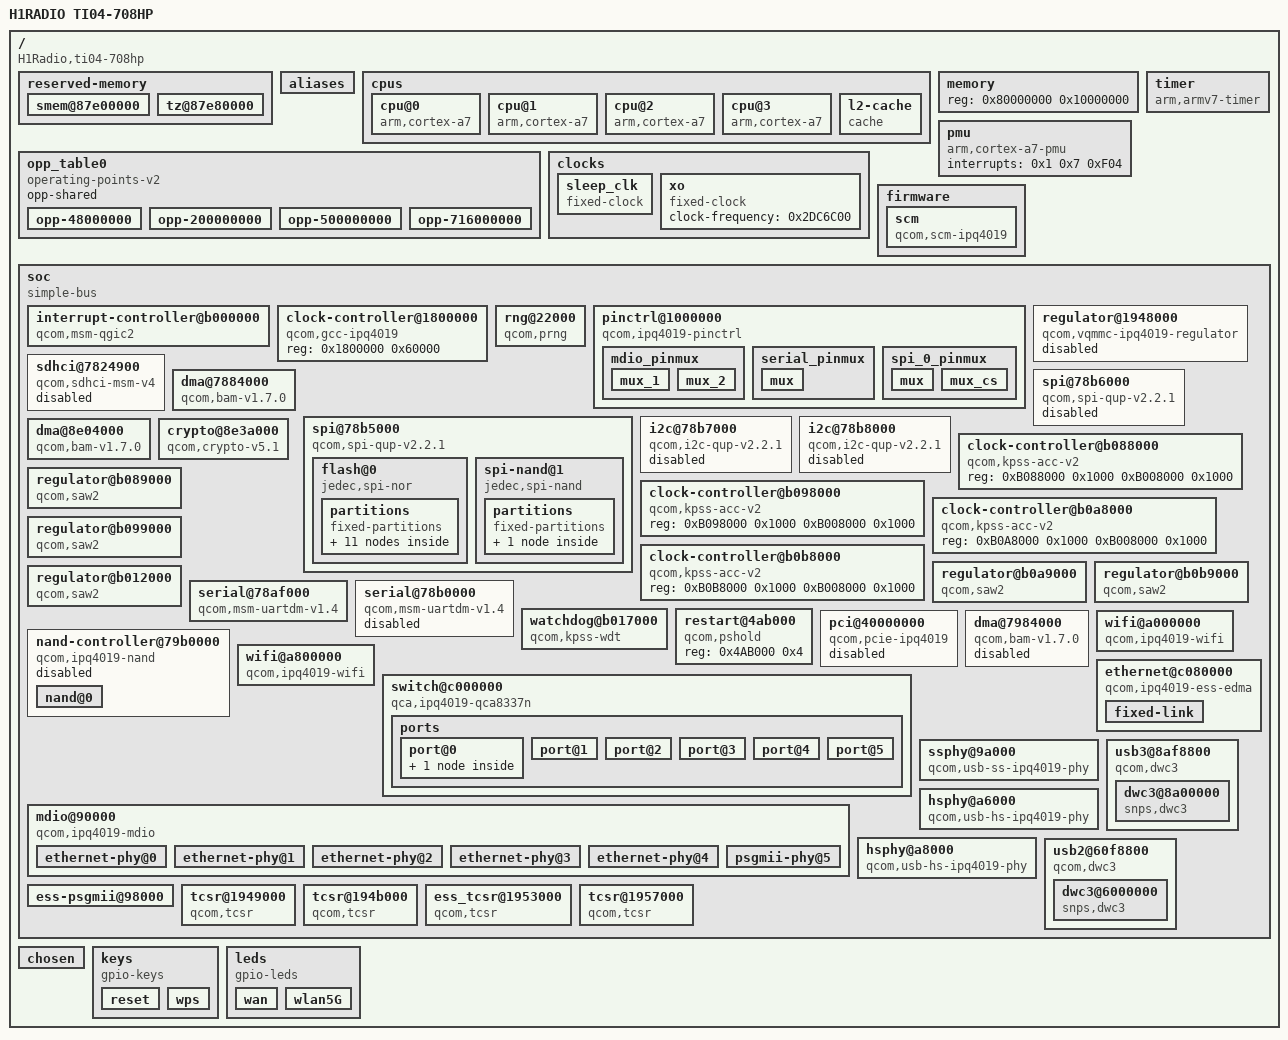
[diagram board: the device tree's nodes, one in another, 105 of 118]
/dts-v1/;
// version: 17
// last_comp_version: 16
// boot_cpuid_phys: 0x0

/ {
    #address-cells = <0x1>;
    #size-cells = <0x1>;
    model = "H1RADIO TI04-708HP";
    compatible = "H1Radio,ti04-708hp";
    interrupt-parent = <0x1>;
    reserved-memory {
        #address-cells = <0x1>;
        #size-cells = <0x1>;
        ranges;
        smem@87e00000 {
            reg = <0x87E00000 0x80000>;
            no-map;
        };
        tz@87e80000 {
            reg = <0x87E80000 0x180000>;
            no-map;
        };
    };
    aliases {
        spi0 = "/soc/spi@78b5000";
        spi1 = "/soc/spi@78b6000";
        i2c0 = "/soc/i2c@78b7000";
        i2c1 = "/soc/i2c@78b8000";
        ethernet0 = "/soc/ethernet@c080000";
        led-boot = "/leds/wan";
        led-failsafe = "/leds/wan";
        led-upgrade = "/leds/wan";
    };
    cpus {
        #address-cells = <0x1>;
        #size-cells = <0x0>;
        cpu@0 {
            device_type = "cpu";
            compatible = "arm,cortex-a7";
            enable-method = "qcom,kpss-acc-v2";
            next-level-cache = <0x2>;
            qcom,acc = <0x3>;
            qcom,saw = <0x4>;
            reg = <0x0>;
            clocks = <0x5 0x9>;
            clock-frequency = <0x0>;
            clock-latency = <0x3E800>;
            operating-points-v2 = <0x6>;
        };
        cpu@1 {
            device_type = "cpu";
            compatible = "arm,cortex-a7";
            enable-method = "qcom,kpss-acc-v2";
            next-level-cache = <0x2>;
            qcom,acc = <0x7>;
            qcom,saw = <0x8>;
            reg = <0x1>;
            clocks = <0x5 0x9>;
            clock-frequency = <0x0>;
            clock-latency = <0x3E800>;
            operating-points-v2 = <0x6>;
        };
        cpu@2 {
            device_type = "cpu";
            compatible = "arm,cortex-a7";
            enable-method = "qcom,kpss-acc-v2";
            next-level-cache = <0x2>;
            qcom,acc = <0x9>;
            qcom,saw = <0xA>;
            reg = <0x2>;
            clocks = <0x5 0x9>;
            clock-frequency = <0x0>;
            clock-latency = <0x3E800>;
            operating-points-v2 = <0x6>;
        };
        cpu@3 {
            device_type = "cpu";
            compatible = "arm,cortex-a7";
            enable-method = "qcom,kpss-acc-v2";
            next-level-cache = <0x2>;
            qcom,acc = <0xB>;
            qcom,saw = <0xC>;
            reg = <0x3>;
            clocks = <0x5 0x9>;
            clock-frequency = <0x0>;
            clock-latency = <0x3E800>;
            operating-points-v2 = <0x6>;
        };
        l2-cache {
            compatible = "cache";
            cache-level = <0x2>;
            qcom,saw = <0xD>;
            phandle = <0x2>;
        };
    };
    opp_table0 {
        compatible = "operating-points-v2";
        opp-shared;
        phandle = <0x6>;
        opp-48000000 {
            opp-hz = <0x0 0x2DC6C00>;
            clock-latency-ns = <0x3E800>;
        };
        opp-200000000 {
            opp-hz = <0x0 0xBEBC200>;
            clock-latency-ns = <0x3E800>;
        };
        opp-500000000 {
            opp-hz = <0x0 0x1DCD6500>;
            clock-latency-ns = <0x3E800>;
        };
        opp-716000000 {
            opp-hz = <0x0 0x2AAD4B00>;
            clock-latency-ns = <0x3E800>;
        };
    };
    memory {
        device_type = "memory";
        reg = <0x80000000 0x10000000>;
    };
    pmu {
        compatible = "arm,cortex-a7-pmu";
        interrupts = <0x1 0x7 0xF04>;
    };
    clocks {
        sleep_clk {
            compatible = "fixed-clock";
            clock-frequency = <0x7D00>;
            clock-output-names = "gcc_sleep_clk_src";
            #clock-cells = <0x0>;
            phandle = <0x13>;
        };
        xo {
            compatible = "fixed-clock";
            clock-frequency = <0x2DC6C00>;
            #clock-cells = <0x0>;
        };
    };
    firmware {
        scm {
            compatible = "qcom,scm-ipq4019";
        };
    };
    timer {
        compatible = "arm,armv7-timer";
        interrupts = <0x1 0x2 0xF08 0x1 0x3 0xF08 0x1 0x4 0xF08 0x1 0x1 0xF08>;
        clock-frequency = <0x2DC6C00>;
        always-on;
    };
    soc {
        #address-cells = <0x1>;
        #size-cells = <0x1>;
        ranges;
        compatible = "simple-bus";
        interrupt-controller@b000000 {
            compatible = "qcom,msm-qgic2";
            interrupt-controller;
            #interrupt-cells = <0x3>;
            reg = <0xB000000 0x1000 0xB002000 0x1000>;
            phandle = <0x1>;
        };
        clock-controller@1800000 {
            compatible = "qcom,gcc-ipq4019";
            #clock-cells = <0x1>;
            #reset-cells = <0x1>;
            reg = <0x1800000 0x60000>;
            phandle = <0x5>;
        };
        rng@22000 {
            compatible = "qcom,prng";
            reg = <0x22000 0x140>;
            clocks = <0x5 0x2B>;
            clock-names = "core";
            status = "okay";
        };
        pinctrl@1000000 {
            compatible = "qcom,ipq4019-pinctrl";
            reg = <0x1000000 0x300000>;
            gpio-controller;
            gpio-ranges = <0xE 0x0 0x0 0x64>;
            #gpio-cells = <0x2>;
            interrupt-controller;
            #interrupt-cells = <0x2>;
            interrupts = <0x0 0xD0 0x4>;
            phandle = <0xE>;
            mdio_pinmux {
                phandle = <0x20>;
                mux_1 {
                    pins = "gpio53";
                    function = "mdio";
                    bias-pull-up;
                };
                mux_2 {
                    pins = "gpio52";
                    function = "mdc";
                    bias-pull-up;
                };
            };
            serial_pinmux {
                phandle = <0x12>;
                mux {
                    pins = "gpio60", "gpio61";
                    function = "blsp_uart0";
                    bias-disable;
                };
            };
            spi_0_pinmux {
                phandle = <0x10>;
                mux {
                    function = "blsp_spi0";
                    pins = "gpio55", "gpio56", "gpio57";
                    drive-strength = <0xC>;
                    bias-disable;
                };
                mux_cs {
                    function = "gpio";
                    pins = "gpio54", "gpio59";
                    drive-strength = <0x2>;
                    bias-disable;
                    output-high;
                };
            };
        };
        regulator@1948000 {
            compatible = "qcom,vqmmc-ipq4019-regulator";
            reg = <0x1948000 0x4>;
            regulator-name = "vqmmc";
            regulator-min-microvolt = <0x16E360>;
            regulator-max-microvolt = <0x2DC6C0>;
            regulator-always-on;
            status = "disabled";
        };
        sdhci@7824900 {
            compatible = "qcom,sdhci-msm-v4";
            reg = <0x7824900 0x11C 0x7824000 0x800>;
            interrupts = <0x0 0x7B 0x4 0x0 0x8A 0x4>;
            interrupt-names = "hc_irq", "pwr_irq";
            bus-width = <0x8>;
            clocks = <0x5 0x2F 0x5 0x2E 0x5 0x1C>;
            clock-names = "core", "iface", "xo";
            status = "disabled";
        };
        dma@7884000 {
            compatible = "qcom,bam-v1.7.0";
            reg = <0x7884000 0x23000>;
            interrupts = <0x0 0xEE 0x4>;
            clocks = <0x5 0x15>;
            clock-names = "bam_clk";
            #dma-cells = <0x1>;
            qcom,ee = <0x0>;
            status = "okay";
            phandle = <0xF>;
        };
        spi@78b5000 {
            compatible = "qcom,spi-qup-v2.2.1";
            reg = <0x78B5000 0x600>;
            interrupts = <0x0 0x5F 0x4>;
            clocks = <0x5 0x17 0x5 0x15>;
            clock-names = "core", "iface";
            #address-cells = <0x1>;
            #size-cells = <0x0>;
            dmas = <0xF 0x5 0xF 0x4>;
            dma-names = "rx", "tx";
            status = "okay";
            pinctrl-0 = <0x10>;
            pinctrl-names = "default";
            cs-gpios = <0xE 0x36 0x0 0xE 0x3B 0x0>;
            flash@0 {
                compatible = "jedec,spi-nor";
                reg = <0x0>;
                linux,modalias = "m25p80", "mx25l1606e", "n25q128a11";
                spi-max-frequency = <0x1C9C380>;
                partitions {
                    compatible = "fixed-partitions";
                    #address-cells = <0x1>;
                    #size-cells = <0x1>;
                    partition@0 {
                        label = "SBL1";
                        reg = <0x0 0x40000>;
                        read-only;
                    };
                    partition@40000 {
                        label = "MIBIB";
                        reg = <0x40000 0x20000>;
                        read-only;
                    };
                    partition@60000 {
                        label = "QSEE";
                        reg = <0x60000 0x60000>;
                        read-only;
                    };
                    partition@c0000 {
                        label = "CDT";
                        reg = <0xC0000 0x10000>;
                        read-only;
                    };
                    partition@d0000 {
                        label = "DDRPARAMS";
                        reg = <0xD0000 0x10000>;
                        read-only;
                    };
                    partition@e0000 {
                        label = "APPSBLENV";
                        reg = <0xE0000 0x10000>;
                        read-only;
                    };
                    partition@f0000 {
                        label = "APPSBL";
                        reg = <0xF0000 0x80000>;
                        read-only;
                    };
                    partition@170000 {
                        label = "ART";
                        reg = <0x170000 0x10000>;
                        read-only;
                        compatible = "nvmem-cells";
                        macaddr@0006 {
                            reg = <0x6 0x6>;
                            phandle = <0x16>;
                        };
                        precal@1000 {
                            reg = <0x1000 0x2F20>;
                            phandle = <0x15>;
                        };
                        precal@5000 {
                            reg = <0x5000 0x2F20>;
                            phandle = <0x17>;
                        };
                    };
                };
            };
            spi-nand@1 {
                compatible = "jedec,spi-nand", "spinand,mt29f";
                #address-cells = <0x1>;
                #size-cells = <0x1>;
                reg = <0x1>;
                spi-max-frequency = <0x16E3600>;
                partitions {
                    compatible = "fixed-partitions";
                    #address-cells = <0x1>;
                    #size-cells = <0x1>;
                    partition@0 {
                        label = "ubi";
                        reg = <0x0 0x8000000>;
                    };
                };
            };
        };
        spi@78b6000 {
            compatible = "qcom,spi-qup-v2.2.1";
            reg = <0x78B6000 0x600>;
            interrupts = <0x0 0x60 0x4>;
            clocks = <0x5 0x19 0x5 0x15>;
            clock-names = "core", "iface";
            #address-cells = <0x1>;
            #size-cells = <0x0>;
            dmas = <0xF 0x7 0xF 0x6>;
            dma-names = "rx", "tx";
            status = "disabled";
        };
        i2c@78b7000 {
            compatible = "qcom,i2c-qup-v2.2.1";
            reg = <0x78B7000 0x600>;
            interrupts = <0x0 0x61 0x4>;
            clocks = <0x5 0x15 0x5 0x16>;
            clock-names = "iface", "core";
            #address-cells = <0x1>;
            #size-cells = <0x0>;
            dmas = <0xF 0x9 0xF 0x8>;
            dma-names = "rx", "tx";
            status = "disabled";
        };
        i2c@78b8000 {
            compatible = "qcom,i2c-qup-v2.2.1";
            reg = <0x78B8000 0x600>;
            interrupts = <0x0 0x62 0x4>;
            clocks = <0x5 0x15 0x5 0x18>;
            clock-names = "iface", "core";
            #address-cells = <0x1>;
            #size-cells = <0x0>;
            dmas = <0xF 0xB 0xF 0xA>;
            dma-names = "rx", "tx";
            status = "disabled";
        };
        dma@8e04000 {
            compatible = "qcom,bam-v1.7.0";
            reg = <0x8E04000 0x20000>;
            interrupts = <0x0 0xCF 0x4>;
            clocks = <0x5 0x21>;
            clock-names = "bam_clk";
            #dma-cells = <0x1>;
            qcom,ee = <0x1>;
            qcom,controlled-remotely;
            status = "okay";
            phandle = <0x11>;
        };
        crypto@8e3a000 {
            compatible = "qcom,crypto-v5.1";
            reg = <0x8E3A000 0x6000>;
            clocks = <0x5 0x21 0x5 0x22 0x5 0x23>;
            clock-names = "iface", "bus", "core";
            dmas = <0x11 0x2 0x11 0x3>;
            dma-names = "rx", "tx";
            status = "okay";
        };
        clock-controller@b088000 {
            compatible = "qcom,kpss-acc-v2";
            reg = <0xB088000 0x1000 0xB008000 0x1000>;
            phandle = <0x3>;
        };
        clock-controller@b098000 {
            compatible = "qcom,kpss-acc-v2";
            reg = <0xB098000 0x1000 0xB008000 0x1000>;
            phandle = <0x7>;
        };
        clock-controller@b0a8000 {
            compatible = "qcom,kpss-acc-v2";
            reg = <0xB0A8000 0x1000 0xB008000 0x1000>;
            phandle = <0x9>;
        };
        clock-controller@b0b8000 {
            compatible = "qcom,kpss-acc-v2";
            reg = <0xB0B8000 0x1000 0xB008000 0x1000>;
            phandle = <0xB>;
        };
        regulator@b089000 {
            compatible = "qcom,saw2";
            reg = <0xB089000 0x1000 0xB009000 0x1000>;
            regulator;
            phandle = <0x4>;
        };
        regulator@b099000 {
            compatible = "qcom,saw2";
            reg = <0xB099000 0x1000 0xB009000 0x1000>;
            regulator;
            phandle = <0x8>;
        };
        regulator@b0a9000 {
            compatible = "qcom,saw2";
            reg = <0xB0A9000 0x1000 0xB009000 0x1000>;
            regulator;
            phandle = <0xA>;
        };
        regulator@b0b9000 {
            compatible = "qcom,saw2";
            reg = <0xB0B9000 0x1000 0xB009000 0x1000>;
            regulator;
            phandle = <0xC>;
        };
        regulator@b012000 {
            compatible = "qcom,saw2";
            reg = <0xB012000 0x1000>;
            regulator;
            phandle = <0xD>;
        };
        serial@78af000 {
            compatible = "qcom,msm-uartdm-v1.4", "qcom,msm-uartdm";
            reg = <0x78AF000 0x200>;
            interrupts = <0x0 0x6B 0x4>;
            status = "okay";
            clocks = <0x5 0x1A 0x5 0x15>;
            clock-names = "core", "iface";
            dmas = <0xF 0x1 0xF 0x0>;
            dma-names = "rx", "tx";
            pinctrl-0 = <0x12>;
            pinctrl-names = "default";
        };
        serial@78b0000 {
            compatible = "qcom,msm-uartdm-v1.4", "qcom,msm-uartdm";
            reg = <0x78B0000 0x200>;
            interrupts = <0x0 0x6C 0x4>;
            status = "disabled";
            clocks = <0x5 0x1B 0x5 0x15>;
            clock-names = "core", "iface";
            dmas = <0xF 0x3 0xF 0x2>;
            dma-names = "rx", "tx";
        };
        watchdog@b017000 {
            compatible = "qcom,kpss-wdt", "qcom,kpss-wdt-ipq4019";
            reg = <0xB017000 0x40>;
            clocks = <0x13>;
            timeout-sec = <0xA>;
            status = "okay";
        };
        restart@4ab000 {
            compatible = "qcom,pshold";
            reg = <0x4AB000 0x4>;
        };
        pci@40000000 {
            compatible = "qcom,pcie-ipq4019", "snps,dw-pcie";
            reg = <0x40000000 0xF1D 0x40000F20 0xA8 0x80000 0x2000 0x40100000 0x1000>;
            reg-names = "dbi", "elbi", "parf", "config";
            device_type = "pci";
            linux,pci-domain = <0x0>;
            bus-range = <0x0 0xFF>;
            num-lanes = <0x1>;
            #address-cells = <0x3>;
            #size-cells = <0x2>;
            ranges = <0x81000000 0x0 0x0 0x40200000 0x0 0x100000 0x82000000 0x0 0x40300000 0x40300000 0x0 0xD00000>;
            interrupts = <0x0 0x8D 0x4>;
            interrupt-names = "msi";
            #interrupt-cells = <0x1>;
            interrupt-map-mask = <0x0 0x0 0x0 0x7>;
            interrupt-map = <0x0 0x0 0x0 0x1 0x1 0x0 0x8E 0x4 0x0 0x0 0x0 0x2 0x1 0x0 0x8F 0x4 0x0 0x0 0x0 0x3 0x1 0x0 0x90 0x4 0x0 0x0 0x0 0x4 0x1 0x0 0x91 0x4>;
            clocks = <0x5 0x27 0x5 0x28 0x5 0x29>;
            clock-names = "aux", "master_bus", "slave_bus";
            resets = <0x5 0x1C 0x5 0x1B 0x5 0x1A 0x5 0x19 0x5 0x18 0x5 0x17 0x5 0x16 0x5 0x15 0x5 0x14 0x5 0x13 0x5 0x12 0x5 0x11>;
            reset-names = "axi_m", "axi_s", "pipe", "axi_m_vmid", "axi_s_xpu", "parf", "phy", "axi_m_sticky", "pipe_sticky", "pwr", "ahb", "phy_ahb";
            status = "disabled";
        };
        dma@7984000 {
            compatible = "qcom,bam-v1.7.0";
            reg = <0x7984000 0x1A000>;
            interrupts = <0x0 0x65 0x4>;
            clocks = <0x5 0x2D>;
            clock-names = "bam_clk";
            #dma-cells = <0x1>;
            qcom,ee = <0x0>;
            status = "disabled";
            phandle = <0x14>;
        };
        nand-controller@79b0000 {
            compatible = "qcom,ipq4019-nand";
            reg = <0x79B0000 0x1000>;
            #address-cells = <0x1>;
            #size-cells = <0x0>;
            clocks = <0x5 0x2D 0x5 0x2C>;
            clock-names = "core", "aon";
            dmas = <0x14 0x0 0x14 0x1 0x14 0x2>;
            dma-names = "tx", "rx", "cmd";
            status = "disabled";
            nand@0 {
                reg = <0x0>;
                nand-ecc-strength = <0x4>;
                nand-ecc-step-size = <0x200>;
                nand-bus-width = <0x8>;
            };
        };
        wifi@a000000 {
            compatible = "qcom,ipq4019-wifi";
            reg = <0xA000000 0x200000>;
            resets = <0x5 0x0 0x5 0x1 0x5 0x2 0x5 0x3 0x5 0x4 0x5 0x5>;
            reset-names = "wifi_cpu_init", "wifi_radio_srif", "wifi_radio_warm", "wifi_radio_cold", "wifi_core_warm", "wifi_core_cold";
            clocks = <0x5 0x3B 0x5 0x3C 0x5 0x3D>;
            clock-names = "wifi_wcss_cmd", "wifi_wcss_ref", "wifi_wcss_rtc";
            interrupts = <0x0 0x20 0x1 0x0 0x21 0x1 0x0 0x22 0x1 0x0 0x23 0x1 0x0 0x24 0x1 0x0 0x25 0x1 0x0 0x26 0x1 0x0 0x27 0x1 0x0 0x28 0x1 0x0 0x29 0x1 0x0 0x2A 0x1 0x0 0x2B 0x1 0x0 0x2C 0x1 0x0 0x2D 0x1 0x0 0x2E 0x1 0x0 0x2F 0x1 0x0 0xA8 0x4>;
            interrupt-names = "msi0", "msi1", "msi2", "msi3", "msi4", "msi5", "msi6", "msi7", "msi8", "msi9", "msi10", "msi11", "msi12", "msi13", "msi14", "msi15", "legacy";
            status = "okay";
            nvmem-cell-names = "pre-calibration", "mac-address";
            nvmem-cells = <0x15 0x16>;
            qcom,ath10k-calibration-variant = "8devices-Jalapeno";
        };
        wifi@a800000 {
            compatible = "qcom,ipq4019-wifi";
            reg = <0xA800000 0x200000>;
            resets = <0x5 0x6 0x5 0x7 0x5 0x8 0x5 0x9 0x5 0xA 0x5 0xB>;
            reset-names = "wifi_cpu_init", "wifi_radio_srif", "wifi_radio_warm", "wifi_radio_cold", "wifi_core_warm", "wifi_core_cold";
            clocks = <0x5 0x3E 0x5 0x3F 0x5 0x40>;
            clock-names = "wifi_wcss_cmd", "wifi_wcss_ref", "wifi_wcss_rtc";
            interrupts = <0x0 0x30 0x1 0x0 0x31 0x1 0x0 0x32 0x1 0x0 0x33 0x1 0x0 0x34 0x1 0x0 0x35 0x1 0x0 0x36 0x1 0x0 0x37 0x1 0x0 0x38 0x1 0x0 0x39 0x1 0x0 0x3A 0x1 0x0 0x3B 0x1 0x0 0x3C 0x1 0x0 0x3D 0x1 0x0 0x3E 0x1 0x0 0x3F 0x1 0x0 0xA9 0x4>;
            interrupt-names = "msi0", "msi1", "msi2", "msi3", "msi4", "msi5", "msi6", "msi7", "msi8", "msi9", "msi10", "msi11", "msi12", "msi13", "msi14", "msi15", "legacy";
            status = "okay";
            nvmem-cell-names = "pre-calibration", "mac-address";
            nvmem-cells = <0x17 0x16>;
            mac-address-increment = <0x1>;
            qcom,ath10k-calibration-variant = "8devices-Jalapeno";
        };
        switch@c000000 {
            compatible = "qca,ipq4019-qca8337n";
            reg = <0xC000000 0x80000 0x98000 0x800>;
            reg-names = "base", "psgmii_phy";
            resets = <0x5 0x4D>;
            reset-names = "psgmii_rst";
            mdio = <0x18>;
            psgmii-ethphy = <0x19>;
            status = "okay";
            ports {
                #address-cells = <0x1>;
                #size-cells = <0x0>;
                port@0 {
                    reg = <0x0>;
                    label = "cpu";
                    ethernet = <0x1A>;
                    phy-mode = "internal";
                    fixed-link {
                        speed = <0x3E8>;
                        full-duplex;
                        pause;
                        asym-pause;
                    };
                };
                port@1 {
                    reg = <0x1>;
                    label = "wan";
                    phy-handle = <0x1B>;
                    phy-mode = "psgmii";
                    status = "okay";
                    nvmem-cells = <0x16>;
                    mac-address-increment = <0x2>;
                    nvmem-cell-names = "mac-address";
                };
                port@2 {
                    reg = <0x2>;
                    label = "lan4";
                    phy-handle = <0x1C>;
                    phy-mode = "psgmii";
                    status = "okay";
                };
                port@3 {
                    reg = <0x3>;
                    label = "lan3";
                    phy-handle = <0x1D>;
                    phy-mode = "psgmii";
                    status = "okay";
                };
                port@4 {
                    reg = <0x4>;
                    label = "lan2";
                    phy-handle = <0x1E>;
                    phy-mode = "psgmii";
                    status = "okay";
                };
                port@5 {
                    reg = <0x5>;
                    label = "lan1";
                    phy-handle = <0x1F>;
                    phy-mode = "psgmii";
                    status = "okay";
                };
            };
        };
        ethernet@c080000 {
            compatible = "qcom,ipq4019-ess-edma";
            reg = <0xC080000 0x8000>;
            resets = <0x5 0x1D>;
            reset-names = "ess_rst";
            clocks = <0x5 0x24>;
            clock-names = "ess_clk";
            interrupts = <0x0 0x41 0x1 0x0 0x42 0x1 0x0 0x43 0x1 0x0 0x44 0x1 0x0 0x45 0x1 0x0 0x46 0x1 0x0 0x47 0x1 0x0 0x48 0x1 0x0 0x49 0x1 0x0 0x4A 0x1 0x0 0x4B 0x1 0x0 0x4C 0x1 0x0 0x4D 0x1 0x0 0x4E 0x1 0x0 0x4F 0x1 0x0 0x50 0x1 0x0 0xF0 0x1 0x0 0xF1 0x1 0x0 0xF2 0x1 0x0 0xF3 0x1 0x0 0xF4 0x1 0x0 0xF5 0x1 0x0 0xF6 0x1 0x0 0xF7 0x1 0x0 0xF8 0x1 0x0 0xF9 0x1 0x0 0xFA 0x1 0x0 0xFB 0x1 0x0 0xFC 0x1 0x0 0xFD 0x1 0x0 0xFE 0x1 0x0 0xFF 0x1>;
            status = "okay";
            phy-mode = "internal";
            nvmem-cells = <0x16>;
            nvmem-cell-names = "mac-address";
            phandle = <0x1A>;
            fixed-link {
                speed = <0x3E8>;
                full-duplex;
                pause;
                asym-pause;
            };
        };
        mdio@90000 {
            #address-cells = <0x1>;
            #size-cells = <0x0>;
            compatible = "qcom,ipq4019-mdio";
            reg = <0x90000 0x64>;
            status = "okay";
            pinctrl-0 = <0x20>;
            pinctrl-names = "default";
            reset-gpios = <0xE 0x3E 0x1>;
            reset-delay-us = <0x1388>;
            phandle = <0x18>;
            ethernet-phy@0 {
                reg = <0x0>;
                qcom,control-dac = <0x5>;
                phandle = <0x1B>;
            };
            ethernet-phy@1 {
                reg = <0x1>;
                qcom,control-dac = <0x5>;
                phandle = <0x1C>;
            };
            ethernet-phy@2 {
                reg = <0x2>;
                qcom,control-dac = <0x5>;
                phandle = <0x1D>;
            };
            ethernet-phy@3 {
                reg = <0x3>;
                qcom,control-dac = <0x5>;
                phandle = <0x1E>;
            };
            ethernet-phy@4 {
                reg = <0x4>;
                qcom,control-dac = <0x5>;
                phandle = <0x1F>;
            };
            psgmii-phy@5 {
                reg = <0x5>;
                qcom,tx-driver-strength = <0x8>;
                phandle = <0x19>;
            };
        };
        ssphy@9a000 {
            compatible = "qcom,usb-ss-ipq4019-phy";
            #phy-cells = <0x0>;
            reg = <0x9A000 0x800>;
            reg-names = "phy_base";
            resets = <0x5 0xC>;
            reset-names = "por_rst";
            status = "okay";
            phandle = <0x22>;
        };
        hsphy@a6000 {
            compatible = "qcom,usb-hs-ipq4019-phy";
            #phy-cells = <0x0>;
            reg = <0xA6000 0x40>;
            reg-names = "phy_base";
            resets = <0x5 0xD 0x5 0xE>;
            reset-names = "por_rst", "srif_rst";
            status = "okay";
            phandle = <0x21>;
        };
        usb3@8af8800 {
            compatible = "qcom,dwc3";
            reg = <0x8AF8800 0x100>;
            #address-cells = <0x1>;
            #size-cells = <0x1>;
            clocks = <0x5 0x38 0x5 0x39 0x5 0x3A>;
            clock-names = "master", "sleep", "mock_utmi";
            ranges;
            status = "okay";
            dwc3@8a00000 {
                compatible = "snps,dwc3";
                reg = <0x8A00000 0xF8000>;
                interrupts = <0x0 0x84 0x4>;
                phys = <0x21 0x22>;
                phy-names = "usb2-phy", "usb3-phy";
                dr_mode = "host";
            };
        };
        hsphy@a8000 {
            compatible = "qcom,usb-hs-ipq4019-phy";
            #phy-cells = <0x0>;
            reg = <0xA8000 0x40>;
            reg-names = "phy_base";
            resets = <0x5 0xF 0x5 0x10>;
            reset-names = "por_rst", "srif_rst";
            status = "okay";
            phandle = <0x23>;
        };
        usb2@60f8800 {
            compatible = "qcom,dwc3";
            reg = <0x60F8800 0x100>;
            #address-cells = <0x1>;
            #size-cells = <0x1>;
            clocks = <0x5 0x35 0x5 0x36 0x5 0x37>;
            clock-names = "master", "sleep", "mock_utmi";
            ranges;
            status = "okay";
            dwc3@6000000 {
                compatible = "snps,dwc3";
                reg = <0x6000000 0xF8000>;
                interrupts = <0x0 0x88 0x4>;
                phys = <0x23>;
                phy-names = "usb2-phy";
                dr_mode = "host";
            };
        };
        ess-psgmii@98000 {
            status = "okay";
        };
        tcsr@1949000 {
            compatible = "qcom,tcsr";
            reg = <0x1949000 0x100>;
            qcom,wifi_glb_cfg = <0x41000000>;
        };
        tcsr@194b000 {
            compatible = "qcom,tcsr";
            reg = <0x194B000 0x100>;
            qcom,usb-hsphy-mode-select = <0xE700E7>;
        };
        ess_tcsr@1953000 {
            compatible = "qcom,tcsr";
            reg = <0x1953000 0x1000>;
            qcom,ess-interface-select = <0x0>;
        };
        tcsr@1957000 {
            compatible = "qcom,tcsr";
            reg = <0x1957000 0x100>;
            qcom,wifi_noc_memtype_m0_m2 = <0x2222222>;
        };
    };
    chosen {
        bootargs-append = " ubi.mtd=ubi root=/dev/ubiblock0_1";
    };
    keys {
        compatible = "gpio-keys";
        reset {
            label = "reset";
            gpios = <0xE 0x3F 0x1>;
            linux,code = <0x198>;
        };
        wps {
            label = "wps";
            gpios = <0xE 0x2 0x1>;
            linux,code = <0x211>;
        };
    };
    leds {
        compatible = "gpio-leds";
        wan {
            label = "green:wan";
            gpios = <0xE 0x0 0x1>;
        };
        wlan5G {
            label = "green:wlan5G";
            gpios = <0xE 0x3A 0x1>;
            linux,default-trigger = "phy1tpt";
        };
    };
};
